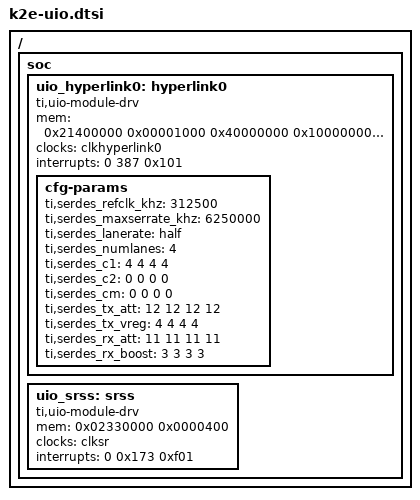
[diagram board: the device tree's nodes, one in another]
/ {
	soc {
		uio_hyperlink0: hyperlink0 {
			compatible = "ti,uio-module-drv";
			mem  = <0x21400000 0x00001000
				0x40000000 0x10000000
				0x0231a000 0x00002000>;
			clocks = <&clkhyperlink0>;
			interrupts	= <0 387 0x101>;
			cfg-params
			{
				ti,serdes_refclk_khz = <312500>;
				ti,serdes_maxserrate_khz = <6250000>;
				ti,serdes_lanerate = "half";
				ti,serdes_numlanes = <4>;
				ti,serdes_c1 = <4 4 4 4>;
				ti,serdes_c2 = <0 0 0 0>;
				ti,serdes_cm = <0 0 0 0>;
				ti,serdes_tx_att = <12 12 12 12>;
				ti,serdes_tx_vreg = <4 4 4 4>;
				ti,serdes_rx_att = <11 11 11 11>;
				ti,serdes_rx_boost = <3 3 3 3>;
			};
		};
		uio_srss: srss {
			compatible = "ti,uio-module-drv";
			mem  = <0x02330000 0x0000400>;
			clocks=<&clksr>;
			interrupts = <0 0x173 0xf01>;
		};
	};
};
